# STM32U345 register map
File version: 1.0
CPU: CM33 r0p1, little endian, MPU, FPU, 4 interrupt priority bits
Registers are 32-bit, read-write, reset 0x0 unless marked. A register's access mark holds for its fields unless they carry their own. Offsets are from the block's base; [hi:lo] are bit positions; {n}, {i} and the like mark numbered series; <NAME> marks a mode.

## PWR — PWR register block
Base 0x40030800
Same registers: PWR_s 0x50030800
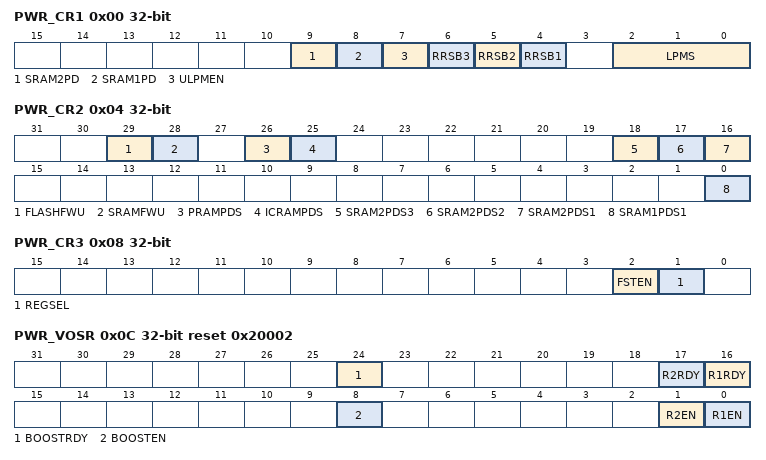
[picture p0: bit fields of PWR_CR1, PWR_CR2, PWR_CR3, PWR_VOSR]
0x00 PWR_CR1 — Power-on reset value: 0x0000 0U00 Exit of Standby mode: not affected This register is protected against nonsecure access when LPMSEC = 1 in PWR_SECCFGR. This register is protected against unprivileged access when LPMSEC = 1 and SPRIV = 1 in PWR_PRIVCFGR, or when LPMSEC = 0 and NSPRIV = 1.
  [9] SRAM2PD — SRAM2 power down This bit is used to reduce the consumption by definitively powering off the SRAM3 until the next power-on reset. Note: This bit is cleared upon power-on reset.
    0=SRAM2 powered on; 1=SRAM2 powered off
  [8] SRAM1PD — SRAM1 power down This bit is used to reduce the consumption by definitively powering off the SRAM1 until the next power-on reset. Note: This bit is cleared upon power-on reset.
    0=SRAM1 powered on; 1=SRAM1 powered off
  [7] ULPMEN — BOR0 ultra-low power mode This bit is used to reduce the consumption by configuring the BOR in discontinuous mode. This bit has effect only when the BOR level 0 is selected, and when the device is in Standby mode. This bit must be set to reach the lowest power consumption in Standby mode.
    0=BOR level 0 operating in continuous (normal) mode in Standby mode; 1=BOR level 0 operating in discontinuous (ultra-low power) mode in Standby mode
  [6] RRSB3 — SRAM2 page 3 retention in Standby mode This bit is used to keep the SRAM2 page 3 content in Standby mode. The SRAM2 page 3 corresponds to the last 8 Kbytes of the SRAM2 (from SRAM2 base address + 0xE000 to SRAM2 base address + 0xFFFF). Note: This bit has no effect in Shutdown mode.
    0=SRAM2 page3 content not retained in Standby mode; 1=SRAM2 page3 content retained in Standby mode
  [5] RRSB2 — SRAM2 page 2 retention in Standby mode This bit is used to keep the SRAM2 page 2 content in Standby mode. The SRAM2 page 2 corresponds to the 24 Kbytes of the SRAM2 (from SRAM2 base address + 0x8000 to SRAM2 base address + 0xDFFF). Note: This bit has no effect in Shutdown mode.
    0=SRAM2 page2 content not retained in Standby mode; 1=SRAM2 page2 content retained in Standby mode
  [4] RRSB1 — SRAM2 page 1 retention in Standby mode This bit is used to keep the SRAM2 page 1 content in Standby mode. The SRAM2 page 1 corresponds to the first 32 Kbytes of the SRAM2 (from SRAM2 base address to SRAM2 base address + 0x7FFF). Note: This bit has no effect in Shutdown mode.
    0=SRAM2 page1 content not retained in Standby mode; 1=SRAM2 page1 content retained in Standby mode
  [2:0] LPMS — Low-power mode selection These bits select the low-power mode entered when the CPU enters Deepsleep mode.
    {v}=Stop {v} mode (v=0..3); 4=Standby mode; 5=Standby mode; 6=Shutdown mode; 7=Shutdown mode
0x04 PWR_CR2 — This register is protected against nonsecure access when LPMSEC = 1 in PWR_SECCFGR. This register is protected against unprivileged access when LPMSEC = 1 and SPRIV = 1 in PWR_PRIVCFGR, or when LPMSEC = 0 and NSPRIV = 1.
  [29] FLASHFWU — Flash memory fast wake-up from Stop 0 and Stop 1 modes This bit is used to obtain the best trade-off between low-power consumption and wake-up time when exiting Stop 0 or Stop 1 modes. When this bit is set, the flash memory remains in normal mode in Stop 0 and Stop 1 modes, which offers a faster startup time with higher consumption.
    0=Flash memory enters low-power mode in Stop 0 and Stop 1 modes (lower-power consumption); 1=Flash memory remains in normal mode in Stop 0 and Stop 1 modes (faster wake-up time)
  [28] SRAMFWU — SRAM fast wake-up from Stop 0 and Stop 1 modes This bit is used to obtain the best trade-off between low-power consumption and wake-up time. SRAMs wake-up time increases the wake-up time when exiting Stop 0 and 1 modes, and also increases the GPDMA1 access time to SRAMs during Stop modes. Note: If one or several SRAMs are configured to be in power-down in Stop 1, Stop 2, and Stop 3 modes through the xRAMyPDS bits, setting this bit has no effect in Stop 1 mode.
    0=SRAMs enter low-power mode in Stop 0 and Stop 1 modes (source biasing for lower-power consumption); 1=SRAMs remain in normal mode in Stop 0 and Stop 1 modes (higher consumption but no SRAM wake-up time)
  [26] PRAMPDS — FDCAN and USB SRAM power-down in Stop 1, Stop 2, and Stop 3 modes
    0=FDCAN and USB SRAM content retained in Stop modes; 1=FDCAN and USB SRAM content lost in Stop modes
  [25] ICRAMPDS — ICACHE SRAM power-down in Stop 1, Stop 2, and Stop 3 modes
    0=ICACHE SRAM content retained in Stop modes; 1=ICACHE SRAM content lost in Stop modes
  [18] SRAM2PDS3 — SRAM2 page 3 (8 Kbytes) power-down in Stop 1, Stop 2, and Stop 3 modes
    0=SRAM2 page 3 content retained in Stop modes; 1=SRAM2 page 3 content lost in Stop modes
  [17] SRAM2PDS2 — SRAM2 page 2 (24 Kbytes) power-down in Stop 1, Stop 2, and Stop 3 modes
    0=SRAM2 page 2 content retained in Stop modes; 1=SRAM2 page 2 content lost in Stop modes
  [16] SRAM2PDS1 — SRAM2 page 1 (32 Kbytes) power-down in Stop 1, Stop 2, and Stop 3 modes
    0=SRAM2 page 1 content retained in Stop modes; 1=SRAM2 page 1 content lost in Stop modes
  [0] SRAM1PDS1 — SRAM1 page i power-down in Stop 1, Stop 2, and Stop 3 modes (i = 7 to 1) Note: Page 1 to 2 size is 16 Kbytes. Page 3 to 7 size is 32 Kbytes.
    0=SRAM1 page i content retained in Stop modes; 1=SRAM1 page i content lost in Stop modes
0x08 PWR_CR3 — System reset value: 0b0000 0000 0000 0000 0000 0000 0000 0U00 Power-on reset Exit of Standby mode: not affected This register is protected against nonsecure access when VDMSEC = 1 in PWR_SECCFGR. This register is protected against unprivileged access when VDMSEC = 1 and SPRIV = 1 in PWR_PRIVCFGR, or when VDMSEC = 0 and NSPRIV = 1.
  [2] FSTEN — Fast soft start
    0=LDO/SMPS fast startup disabled (limited inrush current); 1=LDO/SMPS fast startup enabled
  [1] REGSEL — Regulator selection Note: REGSEL is reserved and must be kept at reset value in packages without SMPS.
    0=LDO selected; 1=SMPS selected
0x0C PWR_VOSR reset 0x20002 — Some register bits are protected against nonsecure access depending on RCC_SECCFGR. These bits can be protected against unprivileged access depending on PWR_PRIVCFGR.
  [24] BOOSTRDY ro — EPOD booster ready This bit is set to 1 by hardware when the power booster startup time is reached. The system clock frequency can be switched higher than 24 MHz only after this bit is set. Disabling the booster clock when the booster is ready is forbidden.
    0=Power booster not ready; 1=Power booster ready
  [17] R2RDY ro — Ready bit for V<sub>CORE</sub> voltage range 2 selection Note: R1RDY and R2RDY cannot be set at the same time.
    0=Range 2 not ready: voltage level less than VOS range 2 level; 1=Range 2 ready: voltage level greater than or equal to VOS range 2 level
  [16] R1RDY ro — Ready bit for V<sub>CORE</sub> voltage range 1 selection Note: R1RDY and R2RDY cannot be set at the same time
    0=Range 1 not ready: voltage level less than VOS range 1 level; 1=Range 1 ready: voltage level greater than or equal to VOS range 1 level
  [8] BOOSTEN — EPOD booster enable This bit is protected against nonsecure access when SYSCLKSEC = 1 in RCC_SECCFGR. It is protected against unprivileged access when SYSCLKSEC = 1 in RCC_SECCFGR and SPRIV = 1 in PWR_PRIVCFGR, or when SYSCLKSEC = 0 and NSPRIV = 1. This bit must be set in range 1, and before increasing the system clock frequency above 24 MHz in range 2. The booster clock must be configured before setting this bit, and must not be disabled as long as the booster is enabled.
    0=Booster disabled; 1=Booster enabled
  [1] R2EN — Voltage scaling range 2 selection This bit is protected against nonsecure access when SYSCLKSEC = 1 in RCC_SECCFGR. It is protected against unprivileged access when SYSCLKSEC = 1 in RCC_SECCFGR and SPRIV = 1 in PWR_PRIVCFGR, or when SYSCLKSEC = 0 and NSPRIV = 1. Note: R1EN and R2EN must be at opposite value. Any attempt to write R1EN and R2EN to the same value is ignored. Modifying R1EN and R2EN is possible only when current range is ready (R1RDY = R1EN and R2RDY = R2EN).
    0=Voltage scaling range 2 disabled; 1=Voltage scaling range 2 enabled
  [0] R1EN — Voltage scaling range 1 selection This bit is protected against nonsecure access when SYSCLKSEC = 1 in RCC_SECCFGR. It is protected against unprivileged access when SYSCLKSEC = 1 in RCC_SECCFGR and SPRIV = 1 in PWR_PRIVCFGR, or when SYSCLKSEC = 0 and NSPRIV = 1. Note: R1EN and R2EN must be at opposite value. Any attempt to write R1EN and R2EN to the same value is ignored. Modifying R1EN and R2EN is possible only when current range is ready (R1RDY = R1EN and R2RDY = R2EN).
    0=Voltage scaling range 1 disabled; 1=Voltage scaling range 1 enabled
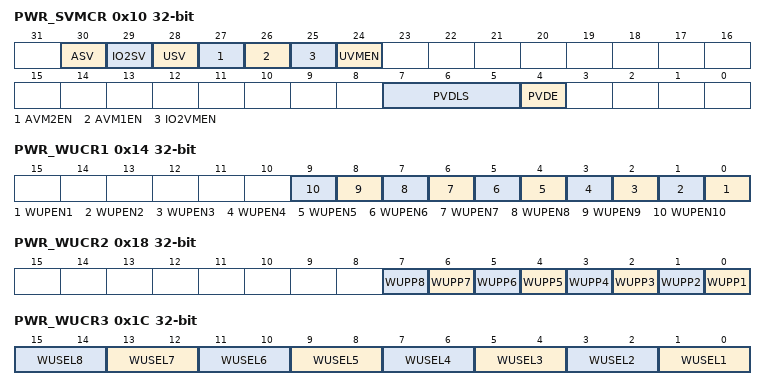
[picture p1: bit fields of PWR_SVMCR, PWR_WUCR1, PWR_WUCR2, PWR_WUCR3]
0x10 PWR_SVMCR — This register is protected against nonsecure access when VDMSEC = 1 in PWR_SECCFGR. This register is protected against unprivileged access when VDMSEC = 1 and SPRIV = 1 in PWR_PRIVCFGR, or when VDMSEC = 0 and NSPRIV = 1.
  [30] ASV — V<sub>DDA</sub> independent analog supply valid This bit is used to validate the V<sub>DDA</sub> supply for electrical and logical isolation purpose. Setting this bit is mandatory to use the analog peripherals. If V<sub>DDA</sub> is not always present in the application, the V<sub>DDA</sub> voltage monitor can be used to determine whether this supply is ready or not.
    0=V<sub>DDA</sub> not present: logical and electrical isolation is applied to ignore this supply; 1=V<sub>DDA</sub> valid
  [29] IO2SV — V<sub>DDIO2</sub> independent I/O supply valid This bit is used to validate the V<sub>DDIO2</sub> supply for electrical and logical isolation purpose. Setting this bit is mandatory to use PG[15:2]. If V<sub>DDIO2</sub> is not always present in the application, the V<sub>DDIO2</sub> voltage monitor can be used to determine whether this supply is ready or not.
    0=V<sub>DDIO2</sub> not present: logical and electrical isolation is applied to ignore this supply; 1=V<sub>DDIO2</sub> valid
  [28] USV — V<sub>DDUSB</sub> independent USB supply valid This bit is used to validate the V<sub>DDUSB</sub> supply for electrical and logical isolation purpose. Setting this bit is mandatory to use the USB peripheral. If V<sub>DDUSB</sub> is not always present in the application, the V<sub>DDUSB</sub> voltage monitor can be used to determine whether this supply is ready or not.
    0=V<sub>DDUSB</sub> not present: logical and electrical isolation is applied to ignore this supply; 1=V<sub>DDUSB</sub> valid
  [27] AVM2EN — V<sub>DDA</sub> independent analog supply voltage monitor 2 enable (1.8 V threshold)
    0=V<sub>DDA</sub> voltage monitor 2 disabled; 1=V<sub>DDA</sub> voltage monitor 2 enabled
  [26] AVM1EN — V<sub>DDA</sub> independent analog supply voltage monitor 1 enable (1.6 V threshold)
    0=V<sub>DDA</sub> voltage monitor 1 disabled; 1=V<sub>DDA</sub> voltage monitor 1 enabled
  [25] IO2VMEN — V<sub>DDIO2</sub> independent I/O voltage monitor enable
    0=V<sub>DDIO2</sub> voltage monitor disabled; 1=V<sub>DDIO2</sub> voltage monitor enabled
  [24] UVMEN — V<sub>DDUSB</sub>independent USB voltage monitor enable
    0=V<sub>DDUSB</sub> voltage monitor disabled; 1=V<sub>DDUSB</sub> voltage monitor enabled
  [7:5] PVDLS — Programmable voltage detector (PVD) level selection These bits select the voltage threshold detected by the PVD.
    0=V<sub>PVD0</sub> around 2.0 V; 1=V<sub>PVD1</sub> around 2.2 V; 2=V<sub>PVD2</sub> around 2.4 V; 3=V<sub>PVD3</sub> around 2.5 V; 4=V<sub>PVD4</sub> around 2.6 V; 5=V<sub>PVD5</sub> around 2.8 V; 6=V<sub>PVD6</sub> around 2.9 V; 7=External input analog voltage PVD_IN (compared internally to VREFINT)
  [4] PVDE — Programmable voltage detector enable
    0=PVD disabled; 1=PVD enabled
0x14 PWR_WUCR1 — Exit of Standby mode: not affected Each bit WUPENi is protected against nonsecure access when WUPiSEC = 1 in PWR_SECCFGR. Each bit WUPENi is protected against unprivileged access when WUPiSEC = 1 in PWR_SECCFGR and SPRIV = 1 in PWR_PRIVCFGR, or when WUPiSEC = 0 and NSPRIV = 1.
  [all] fields
    0=Wake-up line WKUPi disabled; 1=Wake-up line WKUPi enabled
  [n-1] WUPEN{n} (n=1..10) — Wake-up line WKUPi enable
0x18 PWR_WUCR2 — Exit of Standby mode: not affected Each bit WUPPi is protected against nonsecure access when WUPiSEC = 1 in PWR_SECCFGR. Each bit WUPPi is protected against unprivileged access when WUPiSEC = 1 in PWR_SECCFGR and SPRIV = 1 in PWR_PRIVCFGR, or when WUPiSEC = 0 and NSPRIV = 1.
  [all] fields
    0=Detection on high level (rising edge); 1=Detection on low level (falling edge)
  [n-1] WUPP{n} (n=1..8) — Wake-up line WKUP8 polarity This bit must be configured when WUPENi = 0. It has no effect when WUSELi[1:0] = 11.
0x1C PWR_WUCR3 — This register is not modified upon Standby mode exit. Each bit field WUSELi[1:0] is protected against nonsecure access when WUPiSEC = 1 in PWR_SECCFGR. Each bit field WUSELi[1:0] is protected against unprivileged access when WUPiSEC = 1 in PWR_SECCFGR and SPRIV = 1 in PWR_PRIVCFGR, or when WUPiSEC = 0 and NSPRIV = 1.
  [all] fields
    {v}=WKUPi_{v} (v=0..3)
  [2n-1:2n-2] WUSEL{n} (n=1..8) — Wake-up line WKUPi selection This bit field must be configured when WUPENi = 0.
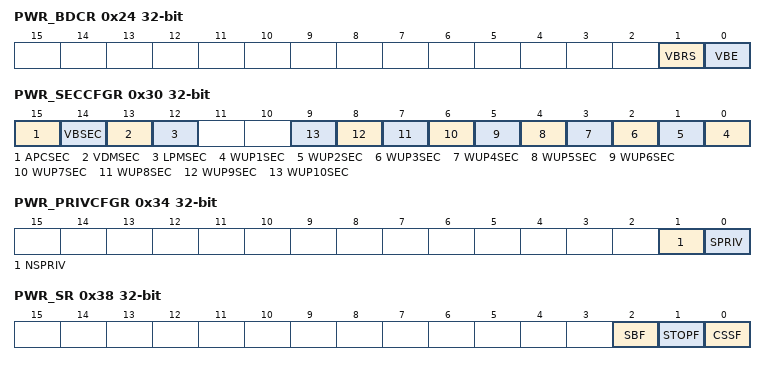
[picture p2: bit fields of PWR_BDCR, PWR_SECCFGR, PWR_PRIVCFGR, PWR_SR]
0x24 PWR_BDCR — System reset value: 0xUUUU UUUU Backup domain reset Exit of Standby mode: not affected This register is protected against nonsecure access when VBSEC = 1 in PWR_SECCFGR. This register is protected against unprivileged access when VBSEC = 1 and SPRIV = 1 in PWR_PRIVCFGR, or when VBSEC = 0 and NSPRIV = 1.
  [1] VBRS — V<sub>BAT</sub> charging resistor selection
    0=V<sub>BAT</sub> charged through a 5 kohm resistor; 1=V<sub>BAT</sub> charged through a 1.5 kohm resistor
  [0] VBE — V<sub>BAT</sub> charging enable
    0=V<sub>BAT</sub> battery charging disabled; 1=V<sub>BAT</sub> battery charging enabled
0x28 PWR_DBPR — This register is protected against nonsecure access when VBSEC = 1 in PWR_SECCFGR. This register is protected against unprivileged access when VBSEC = 1 and SPRIV = 1 in PWR_PRIVCFGR, or when VBSEC = 0 and NSPRIV = 1.
  [0] DBP — Disable backup domain write protection In reset state, all registers and SRAM in backup domain are protected against parasitic write access. This bit must be set to enable the write access to these registers.
    0=Write access to backup domain disabled; 1=Write access to backup domain enabled
0x30 PWR_SECCFGR — This register can be written only when the access is secure. It can be read by secure or nonsecure access. This register is write-protected against unprivileged write access when SPRIV = 1 in PWR_PRIVCFGR.
  [15] APCSEC — Pull-up/pull-down secure protection
    0=PWR_APCR can be read and written with secure or nonsecure access; 1=PWR_APCR can be read and written only with secure access
  [14] VBSEC — Backup domain secure protection
    0=PWR_BDCR and PWR_DBPR can be read and written with secure or nonsecure access; 1=PWR_BDCR and PWR_DBPR can be read and written only with secure access
  [13] VDMSEC — Voltage detection and monitoring secure protection
    0=PWR_SVMCR and PWR_CR3 can be read and written with secure or nonsecure access; 1=PWR_SVMCR and PWR_CR3 can be read and written only with secure access
  [12] LPMSEC — Low-power mode secure protection
    0=PWR_CR1, PWR_CR2, and CSSF bit in the PWR_SR can be read and written with secure or nonsecure access; 1=PWR_CR1, PWR_CR2, and CSSF bit in the PWR_SR can be read and written only with secure access
  [n-1] WUP{n}SEC (n=1..10) — WUPi secure protection
    0=Bits related to the WKUPi line in PWR_WUCR1, PWR_WUCR2, PWR_WUCR3, and PWR_WUSCR can be read and written with secure or nonsecure access; 1=Bits related to the WKUPi line in PWR_WUCR1, PWR_WUCR2, PWR_WUCR3, and PWR_WUSCR can be read and written only with secure access
0x34 PWR_PRIVCFGR — This register can be written only when the access is privileged. It can be read by privileged or unprivileged access
  [1] NSPRIV — PWR nonsecure function privilege configuration This bit is set and reset by software. It can be written only by privileged access, secure or nonsecure.
    0=Read and write to PWR nonsecure functions can be done by privileged or unprivileged access; 1=Read and write to PWR nonsecure functions can be done by privileged access only
  [0] SPRIV — PWR secure function privilege configuration This bit is set and reset by software. It can be written only by a secure privileged access.
    0=Read and write to PWR secure functions can be done by privileged or unprivileged access; 1=Read and write to PWR secure functions can be done by privileged access only
0x38 PWR_SR — Some bits are protected against nonsecure access depending on PWR_SECCFGR. Some bits are protected against unprivileged access depending on PWR_PRIVCFGR.
  [2] SBF ro — Standby flag This bit is set by hardware when the device enters the Standby mode, and is cleared by writing 1 to the CSSF bit, or by a power-on reset. It is not cleared by the system reset.
    0=The device did not enter Standby mode; 1=The device entered Standby mode
  [1] STOPF ro — Stop flag This bit is set by hardware when the device enters a Stop mode, and is cleared by software by writing 1 to the CSSF bit.
    0=The device did not enter any Stop mode; 1=The device entered a Stop mode
  [0] CSSF wo — Clear Stop and Standby flags This bit is protected against nonsecure access when LPMSEC = 1 in PWR_SECCFGR. This bit is protected against unprivileged access when LPMSEC = 1 and SPRIV = 1 in PWR_PRIVCFGR, or when LPMSEC = 0 and NSPRIV = 1. Writing 1 to this bit clears the STOPF and SBF flags.
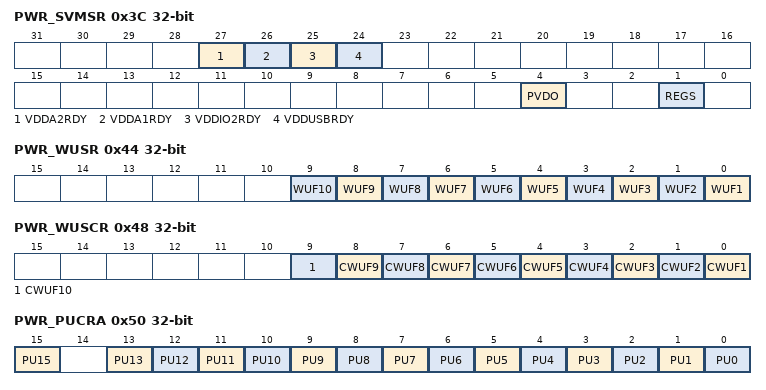
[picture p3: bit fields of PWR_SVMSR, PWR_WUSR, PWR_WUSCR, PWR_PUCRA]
0x3C PWR_SVMSR ro
  [27] VDDA2RDY — V<sub>DDA</sub> ready versus 1.8 V voltage monitor
    0=V<sub>DDA</sub> is below the threshold of the V<sub>DDA</sub> voltage monitor 2 (around 1.8 V); 1=V<sub>DDA</sub> is equal or above the threshold of the V<sub>DDA</sub> voltage monitor 2 (around 1.8 V)
  [26] VDDA1RDY — V<sub>DDA</sub> ready versus 1.6 V voltage monitor
    0=V<sub>DDA</sub> is below the threshold of the V<sub>DDA</sub> voltage monitor 1 (around 1.6 V); 1=V<sub>DDA</sub> is equal or above the threshold of the V<sub>DDA</sub> voltage monitor 1 (around 1.6 V)
  [25] VDDIO2RDY — V<sub>DDIO2 </sub>ready
    0=V<sub>DDIO2</sub> is below the threshold of the V<sub>DDIO2</sub> voltage monitor; 1=V<sub>DDIO2</sub> is equal or above the threshold of the V<sub>DDIO2</sub> voltage monitor
  [24] VDDUSBRDY — V<sub>DDUSB</sub> ready
    0=V<sub>DDUSB</sub> is below the threshold of the V<sub>DDUSB</sub> voltage monitor; 1=V<sub>DDUSB</sub> is equal or above the threshold of the V<sub>DDUSB</sub> voltage monitor
  [4] PVDO — Programmable voltage detector output
    0=V<sub>DD</sub> is equal or above the PVD threshold selected by PVDLS[2:0]; 1=V<sub>DD</sub> is below the PVD threshold selected by PVDLS[2:0]
  [1] REGS — Regulator selection
    0=LDO selected; 1=SMPS selected
0x44 PWR_WUSR ro — Exit of Standby mode: not affected
  [n-1] WUF{n} (n=1..10) — Wake-up flag i This bit is set when a wake-up event is detected on WKUPi line. This bit is cleared by writing 1 in the CWUFi bit of PWR_WUSCR when WUSEL different to 11, or by hardware when WUPENi = 0. If WUSEL = 11, this bit is cleared by hardware when all internal wake-up source are cleared.
0x48 PWR_WUSCR wo — Each bit CWUFi is protected against nonsecure access when WUPiSEC = 1 in PWR_SECCFGR. Each bit CWUFi is protected against unprivileged access when WUPiSEC = 1 in PWR_SECCFGR and SPRIV = 1 in PWR_PRIVCFGR, or when WUPiSEC = 0 and NSPRIV = 1.
  [n-1] CWUF{n} (n=1..10) — Wake-up flag i clear Writing 1 to this bit clears the WUFi flag in PWR_WUSR.
0x4C PWR_APCR — Exit of Standby mode: not affected This register is protected against nonsecure access when APCSEC = 1 in PWR_SECCFGR. This register is protected against unprivileged access when APCSEC = 1 and SPRIV = 1 in PWR_PRIVCFGR, or when APCSEC = 0 and NSPRIV = 1.
  [0] APC — Apply pull-up and pull-down configuration When this bit is set, the I/O pull-up and pull-down configurations defined in PWR_PUCRx and PWR_PDCRx are applied. When this bit is cleared, PWR_PUCRx and PWR_PDCRx are not applied to the I/Os. Note: When APC is set, I/Os configurations from GPIO registers are still applied in Run and Sleep modes (ORed with PWR registers). Care must be taken to define a coherent I/O configuration in GPIO and PWR pull-up/pull-down control registers.
0x50 PWR_PUCRA — Exit of Standby mode: not affected Each bit PUy is protected against nonsecure access when SECy = 1 in GPIOA_SECCFGR. Each bit PUy is protected against unprivileged access when SECy = 1 in GPIOA_SECCFGR and SPRIV = 1 in PWR_PRIVCFGR, or when SECy = 0 and NSPRIV = 1.
  [15] PU15 — Port A pull-up bit 15 When set, each bit activates the pull-up on PA15 when the APC bit is set in PWR_APCR. The pull-up is not activated if the corresponding PD15 bit is also set. Note: The bit is reserved and must be kept to reset value when the corresponding I/O is not available on the selected package.
  [n] PU{n} (n=0..13) — Port A pull-up bit y When set, each bit activates the pull-up on PAy when the APC bit is set in PWR_APCR. The pull-up is not activated if the corresponding PDy bit is also set. Note: The bit is reserved and must be kept to reset value when the corresponding I/O is not available on the selected package.
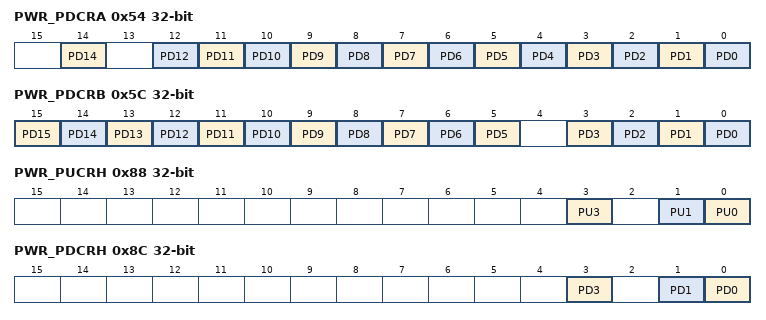
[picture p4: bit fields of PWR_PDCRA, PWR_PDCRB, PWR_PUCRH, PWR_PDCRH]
0x54 PWR_PDCRA — Exit of Standby mode: not affected Each bit PDy is protected against nonsecure access when SECy = 1 in GPIOA_SECCFGR. Each bit PDy is protected against unprivileged access when SECy = 1 in GPIOA_SECCFGR and SPRIV = 1 in PWR_PRIVCFGR, or when SECy = 0 and NSPRIV = 1.
  [14] PD14 — Port A pull-down bit 14 When set, each bit activates the pull-down on PA14 when the APC bit is set in PWR_APCR. Note: The bit is reserved and must be kept to reset value when the corresponding I/O is not available on the selected package.
  [n] PD{n} (n=0..12) — Port A pull-down bit y When set, each bit activates the pull-down on PAy when the APC bit is set in PWR_APCR. Note: The bit is reserved and must be kept to reset value when the corresponding I/O is not available on the selected package.
0x5C PWR_PDCRB — Exit of Standby mode: not affected Each bit PDy is protected against nonsecure access when SECy = 1 in GPIOB_SECCFGR. Each bit PDy is protected against unprivileged access when SECy = 1 in GPIOB_SECCFGR and SPRIV = 1 in PWR_PRIVCFGR, or when SECy = 0 and NSPRIV = 1.
  [n] PD{n} (n=5..15) — Port B pull-down bit y When set, each bit activates the pull-down on PBy when the APC bit is set in PWR_APCR. Note: The bit is reserved and must be kept to reset value when the corresponding I/O is not available on the selected package.
  [n] PD{n} (n=0..3) — Port B pull-down bit y When set, each bit activates the pull-down on PBy when the APC bit is set in PWR_APCR. Note: The bit is reserved and must be kept to reset value when the corresponding I/O is not available on the selected package.
0x88 PWR_PUCRH — Exit of Standby mode: not affected Each bit PUy is protected against nonsecure access when SECy = 1 in GPIOH_SECCFGR. Each bit PUy is protected against unprivileged access when SECy = 1 in GPIOH_SECCFGR and SPRIV = 1 in PWR_PRIVCFGR, or when SECy = 0 and NSPRIV = 1.
  [3] PU3 — Port H pull-up bit 3 When set, each bit activates the pull-up on PH3 when the APC bit is set in PWR_APCR. The pull-up is not activated if the corresponding PD3 bit is also set. Note: The bit is reserved and must be kept to reset value when the corresponding I/O is not available on the selected package.
  [1] PU1 — Port H pull-up bit y When set, each bit activates the pull-up on PHy when the APC bit is set in PWR_APCR. The pull-up is not activated if the corresponding PDy bit is also set. Note: The bit is reserved and must be kept to reset value when the corresponding I/O is not available on the selected package.
  [0] PU0 — Port H pull-up bit y When set, each bit activates the pull-up on PHy when the APC bit is set in PWR_APCR. The pull-up is not activated if the corresponding PDy bit is also set. Note: The bit is reserved and must be kept to reset value when the corresponding I/O is not available on the selected package.
0x8C PWR_PDCRH — Exit of Standby mode: not affected Each bit PDy is protected against nonsecure access when SECy = 1 in GPIOH_SECCFGR. Each bit PDy is protected against unprivileged access when SECy = 1 in GPIOH_SECCFGR and SPRIV = 1 in PWR_PRIVCFGR, or when SECy = 0 and NSPRIV = 1.
  [3] PD3 — Port H pull-down bit 3 When set, each bit activates the pull-down on PH3 when the APC bit is set in PWR_APCR. Note: The bit is reserved and must be kept to reset value when the corresponding I/O is not available on the selected package.
  [1] PD1 — Port H pull-down bit y When set, each bit activates the pull-down on PHy when the APC bit is set in PWR_APCR. Note: The bit is reserved and must be kept to reset value when the corresponding I/O is not available on the selected package.
  [0] PD0 — Port H pull-down bit y When set, each bit activates the pull-down on PHy when the APC bit is set in PWR_APCR. Note: The bit is reserved and must be kept to reset value when the corresponding I/O is not available on the selected package.
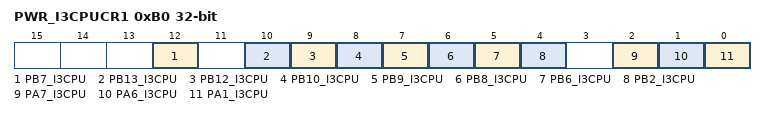
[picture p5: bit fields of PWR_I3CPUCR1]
0xB0 PWR_I3CPUCR1 — Exit of Standby mode: not affected Each bit Pxy_I3CPU is protected against nonsecure access when SECy = 1 in GPIOx_SECCFGR. Each bit Pxy_I3CPU is protected against unprivileged access when SECy = 1 in GPIOx_SECCFGR and SPRIV = 1 in PWR_PRIVCFGR, or when SECy = 0 and NSPRIV = 1.
  [12] PB7_I3CPU — Port B pin 7 I3C pull-up When set, the bit activates the I3C pull-up on PB7. Note: This bit is only available on STM32U3B5/3C5.
  [10] PB13_I3CPU — Port B pin x I3C pull-up When set, the bit activates the I3C pull-up on PBx.
  [9] PB12_I3CPU — Port B pin x I3C pull-up When set, the bit activates the I3C pull-up on PBx.
  [8] PB10_I3CPU — Port B pin y I3C pull-up When set, the bit activates the I3C pull-up on PBy.
  [7] PB9_I3CPU — Port B pin y I3C pull-up When set, the bit activates the I3C pull-up on PBy.
  [6] PB8_I3CPU — Port B pin y I3C pull-up When set, the bit activates the I3C pull-up on PBy.
  [5] PB6_I3CPU — Port B pin 6 I3C pull-up When set, the bit activates the I3C pull-up on PB6.
  [4] PB2_I3CPU — Port B pin 2 I3C pull-up When set, the bit activates the I3C pull-up on PB2.
  [2] PA7_I3CPU — Port A pin y I3C pull-up When set, the bit activates the I3C pull-up on PAy.
  [1] PA6_I3CPU — Port A pin y I3C pull-up When set, the bit activates the I3C pull-up on PAy.
  [0] PA1_I3CPU — Port A pin 1 I3C pull-up When set, the bit activates the I3C pull-up on PA1.
0xB4 PWR_I3CPUCR2 — Exit of Standby mode: not affected Each bit Pxy_I3CPU is protected against nonsecure access when SECy = 1 in GPIOx_SECCFGR. Each bit Pxy_I3CPU is protected against unprivileged access when SECy = 1 in GPIOx_SECCFGR and SPRIV = 1 in PWR_PRIVCFGR, or when SECy = 0 and NSPRIV = 1.
  [11] PH3_I3CPU — Port H pin 3 I3C pull-up When set, the bit activates the I3C pull-up on PH3.
